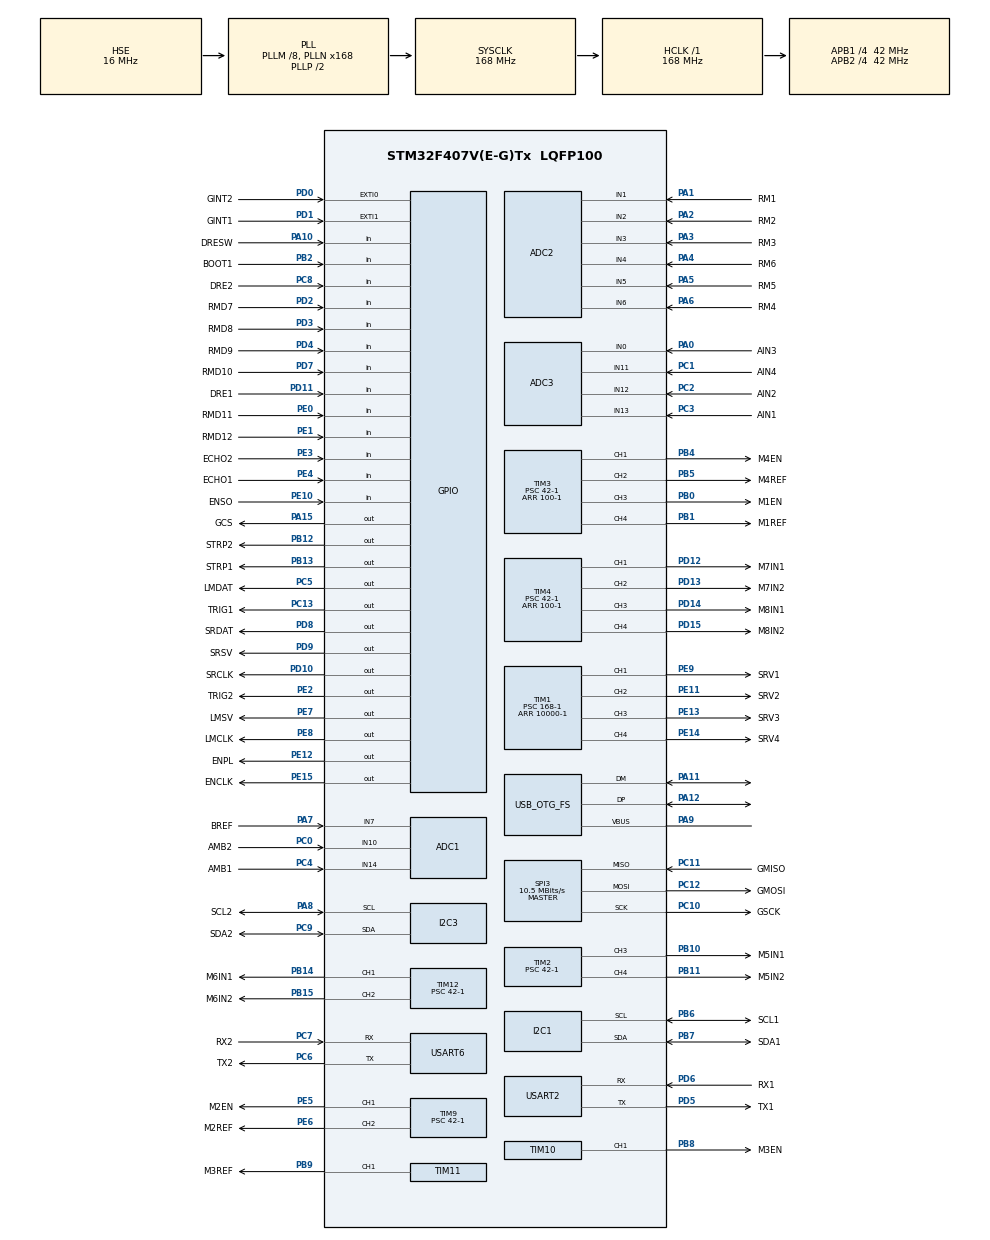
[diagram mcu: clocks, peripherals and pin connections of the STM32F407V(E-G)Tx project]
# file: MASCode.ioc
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ADC1.Channel-0\#ChannelRegularConversion=ADC_CHANNEL_10
ADC1.ClockPrescaler=ADC_CLOCK_SYNC_PCLK_DIV4
ADC1.NbrOfConversionFlag=1
ADC1.Rank-0\#ChannelRegularConversion=1
ADC1.SamplingTime-0\#ChannelRegularConversion=ADC_SAMPLETIME_3CYCLES
ADC1.master=1
ADC2.Channel-0\#ChannelRegularConversion=ADC_CHANNEL_1
ADC2.ClockPrescaler=ADC_CLOCK_SYNC_PCLK_DIV4
ADC2.NbrOfConversionFlag=1
ADC2.Rank-0\#ChannelRegularConversion=1
ADC2.SamplingTime-0\#ChannelRegularConversion=ADC_SAMPLETIME_3CYCLES
ADC3.Channel-0\#ChannelRegularConversion=ADC_CHANNEL_13
ADC3.ClockPrescaler=ADC_CLOCK_SYNC_PCLK_DIV4
ADC3.NbrOfConversionFlag=1
ADC3.Rank-0\#ChannelRegularConversion=1
ADC3.SamplingTime-0\#ChannelRegularConversion=ADC_SAMPLETIME_3CYCLES
Mcu.Family=STM32F4
Mcu.Name=STM32F407V(E-G)Tx
Mcu.Package=LQFP100
NVIC.EXTI0_IRQn=true\:0\:0\:false\:false\:true\:true\:true\:true
NVIC.EXTI1_IRQn=true\:0\:0\:false\:false\:true\:true\:true\:true
NVIC.OTG_FS_IRQn=true\:0\:0\:false\:false\:true\:false\:true\:true
NVIC.PriorityGroup=NVIC_PRIORITYGROUP_4
NVIC.TIM5_IRQn=true\:0\:0\:false\:false\:true\:true\:true\:true
NVIC.TIM7_IRQn=true\:0\:0\:false\:false\:true\:true\:true\:true
PA0-WKUP.GPIO_Label=AIN3
PA0-WKUP.Signal=ADCx_IN0
PA1.GPIO_Label=RM1
PA1.Signal=ADCx_IN1
PA10.GPIO_Label=DRESW
PA10.Signal=GPIO_Input
PA11.Mode=Device_Only
PA11.Signal=USB_OTG_FS_DM
PA12.Mode=Device_Only
PA12.Signal=USB_OTG_FS_DP
PA13.Mode=Trace_Asynchronous_SW
PA13.Signal=SYS_JTMS-SWDIO
PA14.Mode=Trace_Asynchronous_SW
PA14.Signal=SYS_JTCK-SWCLK
PA15.GPIO_Label=GCS
PA15.GPIO_Speed=GPIO_SPEED_FREQ_HIGH
PA15.PinState=GPIO_PIN_SET
PA15.Signal=GPIO_Output
PA2.GPIO_Label=RM2
PA2.Signal=ADCx_IN2
PA3.GPIO_Label=RM3
PA3.Signal=ADCx_IN3
PA4.GPIO_Label=RM6
PA4.Signal=ADCx_IN4
PA5.GPIO_Label=RM5
PA5.Signal=ADCx_IN5
PA6.GPIO_Label=RM4
PA6.Signal=ADCx_IN6
PA7.GPIO_Label=BREF
PA7.Signal=ADCx_IN7
PA8.GPIO_Label=SCL2
PA8.GPIO_Speed=GPIO_SPEED_FREQ_HIGH
PA8.Mode=I2C
PA8.Signal=I2C3_SCL
PA9.Mode=Activate_VBUS
PA9.Signal=USB_OTG_FS_VBUS
PB0.GPIO_Label=M1EN
PB0.Signal=S_TIM3_CH3
PB1.GPIO_Label=M1REF
PB1.Signal=S_TIM3_CH4
PB10.GPIO_Label=M5IN1
PB10.Signal=S_TIM2_CH3
PB11.GPIO_Label=M5IN2
PB11.Signal=S_TIM2_CH4
PB12.GPIO_Label=STRP2
PB12.Signal=GPIO_Output
PB13.GPIO_Label=STRP1
PB13.Signal=GPIO_Output
PB14.GPIO_Label=M6IN1
PB14.Signal=S_TIM12_CH1
PB15.GPIO_Label=M6IN2
PB15.Signal=S_TIM12_CH2
PB2.GPIO_Label=BOOT1
PB2.Signal=GPIO_Input
PB3.Mode=Trace_Asynchronous_SW
PB3.Signal=SYS_JTDO-SWO
PB4.GPIO_Label=M4EN
PB4.Signal=S_TIM3_CH1
PB5.GPIO_Label=M4REF
PB5.Signal=S_TIM3_CH2
PB6.GPIO_Label=SCL1
PB6.GPIO_Speed=GPIO_SPEED_FREQ_HIGH
PB6.Mode=I2C
PB6.Signal=I2C1_SCL
PB7.GPIO_Label=SDA1
PB7.GPIO_Speed=GPIO_SPEED_FREQ_HIGH
PB7.Mode=I2C
PB7.Signal=I2C1_SDA
PB8.GPIO_Label=M3EN
PB8.Signal=S_TIM10_CH1
PB9.GPIO_Label=M3REF
PB9.Signal=S_TIM11_CH1
PC0.GPIO_Label=AMB2
PC0.Signal=ADCx_IN10
PC1.GPIO_Label=AIN4
PC1.Signal=ADCx_IN11
PC10.GPIO_Label=GSCK
PC10.GPIO_Speed=GPIO_SPEED_FREQ_HIGH
PC10.Mode=Full_Duplex_Master
PC10.Signal=SPI3_SCK
PC11.GPIO_Label=GMISO
PC11.GPIO_Speed=GPIO_SPEED_FREQ_HIGH
PC11.Mode=Full_Duplex_Master
PC11.Signal=SPI3_MISO
PC12.GPIO_Label=GMOSI
PC12.GPIO_Speed=GPIO_SPEED_FREQ_HIGH
PC12.Mode=Full_Duplex_Master
PC12.Signal=SPI3_MOSI
PC13-ANTI_TAMP.GPIO_Label=TRIG1
PC13-ANTI_TAMP.Signal=GPIO_Output
PC14-OSC32_IN.Mode=LSE-External-Oscillator
PC14-OSC32_IN.Signal=RCC_OSC32_IN
PC15-OSC32_OUT.Mode=LSE-External-Oscillator
PC15-OSC32_OUT.Signal=RCC_OSC32_OUT
PC2.GPIO_Label=AIN2
PC2.Signal=ADCx_IN12
PC3.GPIO_Label=AIN1
PC3.Signal=ADCx_IN13
PC4.GPIO_Label=AMB1
PC4.Signal=ADCx_IN14
PC5.GPIO_Label=LMDAT
PC5.GPIO_Speed=GPIO_SPEED_FREQ_HIGH
PC5.Signal=GPIO_Output
PC6.GPIO_Label=TX2
PC6.GPIO_Speed=GPIO_SPEED_FREQ_HIGH
PC6.Mode=Asynchronous
PC6.Signal=USART6_TX
PC7.GPIO_Label=RX2
PC7.GPIO_Speed=GPIO_SPEED_FREQ_HIGH
PC7.Mode=Asynchronous
PC7.Signal=USART6_RX
PC8.GPIO_Label=DRE2
PC8.Signal=GPIO_Input
PC9.GPIO_Label=SDA2
PC9.GPIO_Speed=GPIO_SPEED_FREQ_HIGH
PC9.Mode=I2C
PC9.Signal=I2C3_SDA
PD0.GPIO_Label=GINT2
PD0.Signal=GPXTI0
PD1.GPIO_Label=GINT1
PD1.Signal=GPXTI1
PD10.GPIO_Label=SRCLK
PD10.GPIO_Speed=GPIO_SPEED_FREQ_HIGH
PD10.Signal=GPIO_Output
PD11.GPIO_Label=DRE1
PD11.Signal=GPIO_Input
PD12.GPIO_Label=M7IN1
PD12.Signal=S_TIM4_CH1
PD13.GPIO_Label=M7IN2
PD13.Signal=S_TIM4_CH2
PD14.GPIO_Label=M8IN1
PD14.Signal=S_TIM4_CH3
PD15.GPIO_Label=M8IN2
PD15.Signal=S_TIM4_CH4
PD2.GPIO_Label=RMD7
PD2.Signal=GPIO_Input
PD3.GPIO_Label=RMD8
PD3.Signal=GPIO_Input
PD4.GPIO_Label=RMD9
PD4.Signal=GPIO_Input
PD5.GPIO_Label=TX1
PD5.GPIO_Speed=GPIO_SPEED_FREQ_HIGH
PD5.Mode=Asynchronous
PD5.Signal=USART2_TX
PD6.GPIO_Label=RX1
PD6.GPIO_Speed=GPIO_SPEED_FREQ_HIGH
PD6.Mode=Asynchronous
PD6.Signal=USART2_RX
PD7.GPIO_Label=RMD10
PD7.Signal=GPIO_Input
PD8.GPIO_Label=SRDAT
PD8.GPIO_Speed=GPIO_SPEED_FREQ_HIGH
PD8.Signal=GPIO_Output
PD9.GPIO_Label=SRSV
PD9.GPIO_Speed=GPIO_SPEED_FREQ_HIGH
PD9.Signal=GPIO_Output
PE0.GPIO_Label=RMD11
PE0.Signal=GPIO_Input
PE1.GPIO_Label=RMD12
PE1.Signal=GPIO_Input
PE10.GPIO_Label=ENSO
PE10.Signal=GPIO_Input
PE11.GPIO_Label=SRV2
PE11.Signal=S_TIM1_CH2
PE12.GPIO_Label=ENPL
PE12.GPIO_Speed=GPIO_SPEED_FREQ_HIGH
PE12.PinState=GPIO_PIN_RESET
PE12.Signal=GPIO_Output
PE13.GPIO_Label=SRV3
PE13.Signal=S_TIM1_CH3
PE14.GPIO_Label=SRV4
PE14.Signal=S_TIM1_CH4
PE15.GPIO_Label=ENCLK
PE15.GPIO_Speed=GPIO_SPEED_FREQ_HIGH
PE15.PinState=GPIO_PIN_SET
PE15.Signal=GPIO_Output
PE2.GPIO_Label=TRIG2
PE2.Signal=GPIO_Output
PE3.GPIO_Label=ECHO2
PE3.Signal=GPIO_Input
PE4.GPIO_Label=ECHO1
PE4.Signal=GPIO_Input
PE5.GPIO_Label=M2EN
PE5.Signal=S_TIM9_CH1
PE6.GPIO_Label=M2REF
PE6.Signal=S_TIM9_CH2
PE7.GPIO_Label=LMSV
PE7.GPIO_Speed=GPIO_SPEED_FREQ_HIGH
PE7.Signal=GPIO_Output
PE8.GPIO_Label=LMCLK
PE8.GPIO_Speed=GPIO_SPEED_FREQ_HIGH
PE8.Signal=GPIO_Output
PE9.GPIO_Label=SRV1
PE9.Signal=S_TIM1_CH1
PH0-OSC_IN.Mode=HSE-External-Oscillator
PH0-OSC_IN.Signal=RCC_OSC_IN
PH1-OSC_OUT.Mode=HSE-External-Oscillator
PH1-OSC_OUT.Signal=RCC_OSC_OUT
ProjectManager.HeapSize=0x200
ProjectManager.StackSize=0x400
ProjectManager.TargetToolchain=STM32CubeIDE
RCC.48MHZClocksFreq_Value=48000000
RCC.AHBFreq_Value=168000000
RCC.APB1CLKDivider=RCC_HCLK_DIV4
RCC.APB1Freq_Value=42000000
RCC.APB1TimFreq_Value=84000000
RCC.APB2CLKDivider=RCC_HCLK_DIV4
RCC.APB2Freq_Value=42000000
RCC.APB2TimFreq_Value=84000000
RCC.CortexFreq_Value=168000000
RCC.HCLKFreq_Value=168000000
RCC.HSE_VALUE=16000000
RCC.HSI_VALUE=16000000
RCC.PLLM=8
RCC.PLLN=168
RCC.PLLQ=7
RCC.SYSCLKFreq_VALUE=168000000
RCC.SYSCLKSource=RCC_SYSCLKSOURCE_PLLCLK
RCC.VCOOutputFreq_Value=336000000
SH.ADCx_IN0.0=ADC3_IN0,IN0
SH.ADCx_IN1.0=ADC2_IN1,IN1
SH.ADCx_IN10.0=ADC1_IN10,IN10
SH.ADCx_IN11.0=ADC3_IN11,IN11
SH.ADCx_IN12.0=ADC3_IN12,IN12
SH.ADCx_IN13.0=ADC3_IN13,IN13
SH.ADCx_IN14.0=ADC1_IN14,IN14
SH.ADCx_IN2.0=ADC2_IN2,IN2
SH.ADCx_IN3.0=ADC2_IN3,IN3
SH.ADCx_IN4.0=ADC2_IN4,IN4
SH.ADCx_IN5.0=ADC2_IN5,IN5
SH.ADCx_IN6.0=ADC2_IN6,IN6
SH.ADCx_IN7.0=ADC1_IN7,IN7
SH.S_TIM10_CH1.0=TIM10_CH1,PWM Generation1 CH1
SH.S_TIM11_CH1.0=TIM11_CH1,PWM Generation1 CH1
SH.S_TIM12_CH1.0=TIM12_CH1,PWM Generation1 CH1
SH.S_TIM12_CH2.0=TIM12_CH2,PWM Generation2 CH2
SH.S_TIM1_CH1.0=TIM1_CH1,PWM Generation1 CH1
SH.S_TIM1_CH2.0=TIM1_CH2,PWM Generation2 CH2
SH.S_TIM1_CH3.0=TIM1_CH3,PWM Generation3 CH3
SH.S_TIM1_CH4.0=TIM1_CH4,PWM Generation4 CH4
SH.S_TIM2_CH3.0=TIM2_CH3,PWM Generation3 CH3
SH.S_TIM2_CH4.0=TIM2_CH4,PWM Generation4 CH4
SH.S_TIM3_CH1.0=TIM3_CH1,PWM Generation1 CH1
SH.S_TIM3_CH2.0=TIM3_CH2,PWM Generation2 CH2
SH.S_TIM3_CH3.0=TIM3_CH3,PWM Generation3 CH3
SH.S_TIM3_CH4.0=TIM3_CH4,PWM Generation4 CH4
SH.S_TIM4_CH1.0=TIM4_CH1,PWM Generation1 CH1
SH.S_TIM4_CH2.0=TIM4_CH2,PWM Generation2 CH2
SH.S_TIM4_CH3.0=TIM4_CH3,PWM Generation3 CH3
SH.S_TIM4_CH4.0=TIM4_CH4,PWM Generation4 CH4
SH.S_TIM9_CH1.0=TIM9_CH1,PWM Generation1 CH1
SH.S_TIM9_CH2.0=TIM9_CH2,PWM Generation2 CH2
SPI3.BaudRatePrescaler=SPI_BAUDRATEPRESCALER_4
SPI3.CalculateBaudRate=10.5 MBits/s
SPI3.Direction=SPI_DIRECTION_2LINES
SPI3.Mode=SPI_MODE_MASTER
SPI3.VirtualType=VM_MASTER
TIM1.Channel-PWM\ Generation1\ CH1=TIM_CHANNEL_1
TIM1.Channel-PWM\ Generation2\ CH2=TIM_CHANNEL_2
TIM1.Channel-PWM\ Generation3\ CH3=TIM_CHANNEL_3
TIM1.Channel-PWM\ Generation4\ CH4=TIM_CHANNEL_4
TIM1.Period=10000-1
TIM1.Prescaler=168-1
TIM10.Channel=TIM_CHANNEL_1
TIM10.Period=100-1
TIM10.Prescaler=42-1
TIM11.Channel=TIM_CHANNEL_1
TIM11.Period=100-1
TIM11.Prescaler=42-1
TIM12.Channel-PWM\ Generation1\ CH1=TIM_CHANNEL_1
TIM12.Channel-PWM\ Generation2\ CH2=TIM_CHANNEL_2
TIM12.Period=100-1
TIM12.Prescaler=42-1
TIM2.Channel-PWM\ Generation3\ CH3=TIM_CHANNEL_3
TIM2.Channel-PWM\ Generation4\ CH4=TIM_CHANNEL_4
TIM2.Period=100-1
TIM2.Prescaler=42-1
TIM3.Channel-PWM\ Generation1\ CH1=TIM_CHANNEL_1
TIM3.Channel-PWM\ Generation2\ CH2=TIM_CHANNEL_2
TIM3.Channel-PWM\ Generation3\ CH3=TIM_CHANNEL_3
TIM3.Channel-PWM\ Generation4\ CH4=TIM_CHANNEL_4
TIM3.Period=100-1
TIM3.Prescaler=42-1
TIM4.Channel-PWM\ Generation1\ CH1=TIM_CHANNEL_1
TIM4.Channel-PWM\ Generation2\ CH2=TIM_CHANNEL_2
TIM4.Channel-PWM\ Generation3\ CH3=TIM_CHANNEL_3
TIM4.Channel-PWM\ Generation4\ CH4=TIM_CHANNEL_4
TIM4.Period=100-1
TIM4.Prescaler=42-1
TIM5.Period=20-1
TIM5.Prescaler=42-1
TIM7.Prescaler=12
TIM9.Channel-PWM\ Generation1\ CH1=TIM_CHANNEL_1
TIM9.Channel-PWM\ Generation2\ CH2=TIM_CHANNEL_2
TIM9.Period=100-1
TIM9.Prescaler=42-1
USART2.VirtualMode=VM_ASYNC
USART6.VirtualMode=VM_ASYNC
USB_DEVICE.CLASS_NAME_FS=CDC
USB_DEVICE.PRODUCT_STRING_CDC_FS=Electrozilla Virtual ComPort
USB_DEVICE.VirtualMode-CDC_FS=Cdc
USB_DEVICE.VirtualModeFS=Cdc_FS
USB_OTG_FS.VirtualMode=Device_Only
VP_ADC1_TempSens_Input.Mode=IN-TempSens
VP_TIM10_VS_ClockSourceINT.Mode=Enable_Timer
VP_TIM11_VS_ClockSourceINT.Mode=Enable_Timer
VP_TIM12_VS_ClockSourceINT.Mode=Internal
VP_TIM1_VS_ClockSourceINT.Mode=Internal
VP_TIM2_VS_ClockSourceINT.Mode=Internal
VP_TIM3_VS_ClockSourceINT.Mode=Internal
VP_TIM4_VS_ClockSourceINT.Mode=Internal
VP_TIM5_VS_ClockSourceINT.Mode=Internal
VP_TIM7_VS_ClockSourceINT.Mode=Enable_Timer
VP_TIM9_VS_ClockSourceINT.Mode=Internal
VP_USB_DEVICE_VS_USB_DEVICE_CDC_FS.Mode=CDC_FS
board=custom

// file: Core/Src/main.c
/* USER CODE BEGIN Header */
/**
 ******************************************************************************
 * @file           : main.c
 * @brief          : Setup Program body
 ******************************************************************************
 * @attention
 *
 * Copyright (c) 2024 STMicroelectronics.
 * All rights reserved.
 *
 * This software is licensed under terms that can be found in the LICENSE file
 * in the root directory of this software component.
 * If no LICENSE file comes with this software, it is provided AS-IS.
 *
 ******************************************************************************
 */

/*
 * Connection info
 *
 * ADC1 - AMB1, AMB2, BREF
 * ADC2 - RM1:6
 * ADC3 - AIN1:4
 *
 * TIM1 - SRV1:4
 * TIM2 - M5
 * TIM3 - M1, M4
 * TIM4 - M7, M8
 * TIM9 - M2
 * TIM10 - M3EN
 * TIM11 - M3REF
 * TIM12 - M6
 *
 * TIM5 - Shift Register Frames
 * TIM7 - Digital Read Frames
 *
 * I2C1 - External
 * I2C2 - OLED
 *
 * SPI3 - Gyroscope/Accelerometer + Temperature
 *
 * UART2 - External 1
 * UART6 - External 2
 */

/* USER CODE END Header */
#include "main.h"
#include "usb_device.h"

/* USER CODE BEGIN Includes */
#include "usbd_cdc_if.h"
#include "control.h"
#include "registers.h"
/* USER CODE END Includes */

ADC_HandleTypeDef hadc1;
ADC_HandleTypeDef hadc2;
ADC_HandleTypeDef hadc3;

I2C_HandleTypeDef hi2c1;
I2C_HandleTypeDef hi2c3;

SPI_HandleTypeDef hspi3;

TIM_HandleTypeDef htim1;
TIM_HandleTypeDef htim2;
TIM_HandleTypeDef htim3;
TIM_HandleTypeDef htim4;
TIM_HandleTypeDef htim5;
TIM_HandleTypeDef htim7;
TIM_HandleTypeDef htim9;
TIM_HandleTypeDef htim10;
TIM_HandleTypeDef htim11;
TIM_HandleTypeDef htim12;

UART_HandleTypeDef huart2;
UART_HandleTypeDef huart6;

void SystemClock_Config(void);
static void MX_GPIO_Init(void);
static void MX_ADC1_Init(void);
static void MX_I2C1_Init(void);
static void MX_I2C3_Init(void);
static void MX_SPI3_Init(void);
static void MX_TIM1_Init(void);
static void MX_TIM2_Init(void);
static void MX_TIM3_Init(void);
static void MX_TIM4_Init(void);
static void MX_TIM9_Init(void);
static void MX_TIM10_Init(void);
static void MX_TIM11_Init(void);
static void MX_TIM12_Init(void);
static void MX_USART2_UART_Init(void);
static void MX_USART6_UART_Init(void);
static void MX_ADC2_Init(void);
static void MX_ADC3_Init(void);
static void MX_TIM5_Init(void);
static void MX_TIM7_Init(void);

int main(void)
{

  /* MCU Configuration--------------------------------------------------------*/

  /* Reset of all peripherals, Initializes the Flash interface and the Systick. */
  HAL_Init();

  /* Configure the system clock */
  SystemClock_Config();

  /* Initialize all configured peripherals */
  MX_GPIO_Init();
  MX_ADC1_Init();
  MX_I2C1_Init();
  MX_I2C3_Init();
  MX_SPI3_Init();
  MX_TIM1_Init();
  MX_TIM2_Init();
  MX_TIM3_Init();
  MX_TIM4_Init();
  MX_TIM9_Init();
  MX_TIM10_Init();
  MX_TIM11_Init();
  MX_TIM12_Init();
  MX_USART2_UART_Init();
  MX_USART6_UART_Init();
  MX_ADC2_Init();
  MX_ADC3_Init();
  MX_USB_DEVICE_Init();
  MX_TIM5_Init();
  MX_TIM7_Init();
  /* USER CODE BEGIN 2 */
	HAL_Delay(10);

	Control_Init();

	HAL_Delay(10);
  /* USER CODE END 2 */

  /* Infinite loop */
  /* USER CODE BEGIN WHILE */
	while (1) {
		Control_Loop();
    /* USER CODE END WHILE */

	}
}

void SystemClock_Config(void)
{
  RCC_OscInitTypeDef RCC_OscInitStruct = {0};
  RCC_ClkInitTypeDef RCC_ClkInitStruct = {0};

  /** Configure the main internal regulator output voltage
  */
  __HAL_RCC_PWR_CLK_ENABLE();
  __HAL_PWR_VOLTAGESCALING_CONFIG(PWR_REGULATOR_VOLTAGE_SCALE1);

  /** Initializes the RCC Oscillators according to the specified parameters
  * in the RCC_OscInitTypeDef structure.
  */
  RCC_OscInitStruct.OscillatorType = RCC_OSCILLATORTYPE_HSE;
  RCC_OscInitStruct.HSEState = RCC_HSE_ON;
  RCC_OscInitStruct.PLL.PLLState = RCC_PLL_ON;
  RCC_OscInitStruct.PLL.PLLSource = RCC_PLLSOURCE_HSE;
  RCC_OscInitStruct.PLL.PLLM = 8;
  RCC_OscInitStruct.PLL.PLLN = 168;
  RCC_OscInitStruct.PLL.PLLP = RCC_PLLP_DIV2;
  RCC_OscInitStruct.PLL.PLLQ = 7;
  if (HAL_RCC_OscConfig(&RCC_OscInitStruct) != HAL_OK)
  {
    Error_Handler();
  }

  /** Initializes the CPU, AHB and APB buses clocks
  */
  RCC_ClkInitStruct.ClockType = RCC_CLOCKTYPE_HCLK|RCC_CLOCKTYPE_SYSCLK
                              |RCC_CLOCKTYPE_PCLK1|RCC_CLOCKTYPE_PCLK2;
  RCC_ClkInitStruct.SYSCLKSource = RCC_SYSCLKSOURCE_PLLCLK;
  RCC_ClkInitStruct.AHBCLKDivider = RCC_SYSCLK_DIV1;
  RCC_ClkInitStruct.APB1CLKDivider = RCC_HCLK_DIV4;
  RCC_ClkInitStruct.APB2CLKDivider = RCC_HCLK_DIV4;

  if (HAL_RCC_ClockConfig(&RCC_ClkInitStruct, FLASH_LATENCY_5) != HAL_OK)
  {
    Error_Handler();
  }
}

static void MX_ADC1_Init(void)
{

  ADC_ChannelConfTypeDef sConfig = {0};

  /** Configure the global features of the ADC (Clock, Resolution, Data Alignment and number of conversion)
  */
  hadc1.Instance = ADC1;
  hadc1.Init.ClockPrescaler = ADC_CLOCK_SYNC_PCLK_DIV4;
  hadc1.Init.Resolution = ADC_RESOLUTION_12B;
  hadc1.Init.ScanConvMode = DISABLE;
  hadc1.Init.ContinuousConvMode = DISABLE;
  hadc1.Init.DiscontinuousConvMode = DISABLE;
  hadc1.Init.ExternalTrigConvEdge = ADC_EXTERNALTRIGCONVEDGE_NONE;
  hadc1.Init.ExternalTrigConv = ADC_SOFTWARE_START;
  hadc1.Init.DataAlign = ADC_DATAALIGN_RIGHT;
  hadc1.Init.NbrOfConversion = 1;
  hadc1.Init.DMAContinuousRequests = DISABLE;
  hadc1.Init.EOCSelection = ADC_EOC_SINGLE_CONV;
  if (HAL_ADC_Init(&hadc1) != HAL_OK)
  {
    Error_Handler();
  }

  /** Configure for the selected ADC regular channel its corresponding rank in the sequencer and its sample time.
  */
  sConfig.Channel = ADC_CHANNEL_10;
  sConfig.Rank = 1;
  sConfig.SamplingTime = ADC_SAMPLETIME_3CYCLES;
  if (HAL_ADC_ConfigChannel(&hadc1, &sConfig) != HAL_OK)
  {
    Error_Handler();
  }

}

static void MX_ADC2_Init(void)
{

  ADC_ChannelConfTypeDef sConfig = {0};

  /** Configure the global features of the ADC (Clock, Resolution, Data Alignment and number of conversion)
  */
  hadc2.Instance = ADC2;
  hadc2.Init.ClockPrescaler = ADC_CLOCK_SYNC_PCLK_DIV4;
  hadc2.Init.Resolution = ADC_RESOLUTION_12B;
  hadc2.Init.ScanConvMode = DISABLE;
  hadc2.Init.ContinuousConvMode = DISABLE;
  hadc2.Init.DiscontinuousConvMode = DISABLE;
  hadc2.Init.ExternalTrigConvEdge = ADC_EXTERNALTRIGCONVEDGE_NONE;
  hadc2.Init.ExternalTrigConv = ADC_SOFTWARE_START;
  hadc2.Init.DataAlign = ADC_DATAALIGN_RIGHT;
  hadc2.Init.NbrOfConversion = 1;
  hadc2.Init.DMAContinuousRequests = DISABLE;
  hadc2.Init.EOCSelection = ADC_EOC_SINGLE_CONV;
  if (HAL_ADC_Init(&hadc2) != HAL_OK)
  {
    Error_Handler();
  }

  /** Configure for the selected ADC regular channel its corresponding rank in the sequencer and its sample time.
  */
  sConfig.Channel = ADC_CHANNEL_1;
  sConfig.Rank = 1;
  sConfig.SamplingTime = ADC_SAMPLETIME_3CYCLES;
  if (HAL_ADC_ConfigChannel(&hadc2, &sConfig) != HAL_OK)
  {
    Error_Handler();
  }

}

static void MX_ADC3_Init(void)
{

  ADC_ChannelConfTypeDef sConfig = {0};

  /** Configure the global features of the ADC (Clock, Resolution, Data Alignment and number of conversion)
  */
  hadc3.Instance = ADC3;
  hadc3.Init.ClockPrescaler = ADC_CLOCK_SYNC_PCLK_DIV4;
  hadc3.Init.Resolution = ADC_RESOLUTION_12B;
  hadc3.Init.ScanConvMode = DISABLE;
  hadc3.Init.ContinuousConvMode = DISABLE;
  hadc3.Init.DiscontinuousConvMode = DISABLE;
  hadc3.Init.ExternalTrigConvEdge = ADC_EXTERNALTRIGCONVEDGE_NONE;
  hadc3.Init.ExternalTrigConv = ADC_SOFTWARE_START;
  hadc3.Init.DataAlign = ADC_DATAALIGN_RIGHT;
  hadc3.Init.NbrOfConversion = 1;
  hadc3.Init.DMAContinuousRequests = DISABLE;
  hadc3.Init.EOCSelection = ADC_EOC_SINGLE_CONV;
  if (HAL_ADC_Init(&hadc3) != HAL_OK)
  {
    Error_Handler();
  }

  /** Configure for the selected ADC regular channel its corresponding rank in the sequencer and its sample time.
  */
  sConfig.Channel = ADC_CHANNEL_13;
  sConfig.Rank = 1;
  sConfig.SamplingTime = ADC_SAMPLETIME_3CYCLES;
  if (HAL_ADC_ConfigChannel(&hadc3, &sConfig) != HAL_OK)
  {
    Error_Handler();
  }

}

static void MX_I2C1_Init(void)
{

  hi2c1.Instance = I2C1;
  hi2c1.Init.ClockSpeed = 100000;
  hi2c1.Init.DutyCycle = I2C_DUTYCYCLE_2;
  hi2c1.Init.OwnAddress1 = 0;
  hi2c1.Init.AddressingMode = I2C_ADDRESSINGMODE_7BIT;
  hi2c1.Init.DualAddressMode = I2C_DUALADDRESS_DISABLE;
  hi2c1.Init.OwnAddress2 = 0;
  hi2c1.Init.GeneralCallMode = I2C_GENERALCALL_DISABLE;
  hi2c1.Init.NoStretchMode = I2C_NOSTRETCH_DISABLE;
  if (HAL_I2C_Init(&hi2c1) != HAL_OK)
  {
    Error_Handler();
  }

}

static void MX_I2C3_Init(void)
{

  hi2c3.Instance = I2C3;
  hi2c3.Init.ClockSpeed = 100000;
  hi2c3.Init.DutyCycle = I2C_DUTYCYCLE_2;
  hi2c3.Init.OwnAddress1 = 0;
  hi2c3.Init.AddressingMode = I2C_ADDRESSINGMODE_7BIT;
  hi2c3.Init.DualAddressMode = I2C_DUALADDRESS_DISABLE;
  hi2c3.Init.OwnAddress2 = 0;
  hi2c3.Init.GeneralCallMode = I2C_GENERALCALL_DISABLE;
  hi2c3.Init.NoStretchMode = I2C_NOSTRETCH_DISABLE;
  if (HAL_I2C_Init(&hi2c3) != HAL_OK)
  {
    Error_Handler();
  }

}

static void MX_SPI3_Init(void)
{

  /* SPI3 parameter configuration*/
  hspi3.Instance = SPI3;
  hspi3.Init.Mode = SPI_MODE_MASTER;
  hspi3.Init.Direction = SPI_DIRECTION_2LINES;
  hspi3.Init.DataSize = SPI_DATASIZE_8BIT;
  hspi3.Init.CLKPolarity = SPI_POLARITY_LOW;
  hspi3.Init.CLKPhase = SPI_PHASE_1EDGE;
  hspi3.Init.NSS = SPI_NSS_SOFT;
  hspi3.Init.BaudRatePrescaler = SPI_BAUDRATEPRESCALER_4;
  hspi3.Init.FirstBit = SPI_FIRSTBIT_MSB;
  hspi3.Init.TIMode = SPI_TIMODE_DISABLE;
  hspi3.Init.CRCCalculation = SPI_CRCCALCULATION_DISABLE;
  hspi3.Init.CRCPolynomial = 10;
  if (HAL_SPI_Init(&hspi3) != HAL_OK)
  {
    Error_Handler();
  }

}

static void MX_TIM1_Init(void)
{

  TIM_ClockConfigTypeDef sClockSourceConfig = {0};
  TIM_MasterConfigTypeDef sMasterConfig = {0};
  TIM_OC_InitTypeDef sConfigOC = {0};
  TIM_BreakDeadTimeConfigTypeDef sBreakDeadTimeConfig = {0};

  htim1.Instance = TIM1;
  htim1.Init.Prescaler = 168-1;
  htim1.Init.CounterMode = TIM_COUNTERMODE_UP;
  htim1.Init.Period = 10000-1;
  htim1.Init.ClockDivision = TIM_CLOCKDIVISION_DIV1;
  htim1.Init.RepetitionCounter = 0;
  htim1.Init.AutoReloadPreload = TIM_AUTORELOAD_PRELOAD_DISABLE;
  if (HAL_TIM_Base_Init(&htim1) != HAL_OK)
  {
    Error_Handler();
  }
  sClockSourceConfig.ClockSource = TIM_CLOCKSOURCE_INTERNAL;
  if (HAL_TIM_ConfigClockSource(&htim1, &sClockSourceConfig) != HAL_OK)
  {
    Error_Handler();
  }
  if (HAL_TIM_PWM_Init(&htim1) != HAL_OK)
  {
    Error_Handler();
  }
  sMasterConfig.MasterOutputTrigger = TIM_TRGO_RESET;
  sMasterConfig.MasterSlaveMode = TIM_MASTERSLAVEMODE_DISABLE;
  if (HAL_TIMEx_MasterConfigSynchronization(&htim1, &sMasterConfig) != HAL_OK)
  {
    Error_Handler();
  }
  sConfigOC.OCMode = TIM_OCMODE_PWM1;
  sConfigOC.Pulse = 0;
  sConfigOC.OCPolarity = TIM_OCPOLARITY_HIGH;
  sConfigOC.OCNPolarity = TIM_OCNPOLARITY_HIGH;
  sConfigOC.OCFastMode = TIM_OCFAST_DISABLE;
  sConfigOC.OCIdleState = TIM_OCIDLESTATE_RESET;
  sConfigOC.OCNIdleState = TIM_OCNIDLESTATE_RESET;
  if (HAL_TIM_PWM_ConfigChannel(&htim1, &sConfigOC, TIM_CHANNEL_1) != HAL_OK)
  {
    Error_Handler();
  }
  if (HAL_TIM_PWM_ConfigChannel(&htim1, &sConfigOC, TIM_CHANNEL_2) != HAL_OK)
  {
    Error_Handler();
  }
  if (HAL_TIM_PWM_ConfigChannel(&htim1, &sConfigOC, TIM_CHANNEL_3) != HAL_OK)
  {
    Error_Handler();
  }
  if (HAL_TIM_PWM_ConfigChannel(&htim1, &sConfigOC, TIM_CHANNEL_4) != HAL_OK)
  {
    Error_Handler();
  }
  sBreakDeadTimeConfig.OffStateRunMode = TIM_OSSR_DISABLE;
  sBreakDeadTimeConfig.OffStateIDLEMode = TIM_OSSI_DISABLE;
  sBreakDeadTimeConfig.LockLevel = TIM_LOCKLEVEL_OFF;
  sBreakDeadTimeConfig.DeadTime = 0;
  sBreakDeadTimeConfig.BreakState = TIM_BREAK_DISABLE;
  sBreakDeadTimeConfig.BreakPolarity = TIM_BREAKPOLARITY_HIGH;
  sBreakDeadTimeConfig.AutomaticOutput = TIM_AUTOMATICOUTPUT_DISABLE;
  if (HAL_TIMEx_ConfigBreakDeadTime(&htim1, &sBreakDeadTimeConfig) != HAL_OK)
  {
    Error_Handler();
  }
  HAL_TIM_MspPostInit(&htim1);

}

static void MX_TIM2_Init(void)
{

  TIM_ClockConfigTypeDef sClockSourceConfig = {0};
  TIM_MasterConfigTypeDef sMasterConfig = {0};
  TIM_OC_InitTypeDef sConfigOC = {0};

  htim2.Instance = TIM2;
  htim2.Init.Prescaler = 42-1;
  htim2.Init.CounterMode = TIM_COUNTERMODE_UP;
  htim2.Init.Period = 100-1;
  htim2.Init.ClockDivision = TIM_CLOCKDIVISION_DIV1;
  htim2.Init.AutoReloadPreload = TIM_AUTORELOAD_PRELOAD_DISABLE;
  if (HAL_TIM_Base_Init(&htim2) != HAL_OK)
  {
    Error_Handler();
  }
  sClockSourceConfig.ClockSource = TIM_CLOCKSOURCE_INTERNAL;
  if (HAL_TIM_ConfigClockSource(&htim2, &sClockSourceConfig) != HAL_OK)
  {
    Error_Handler();
  }
  if (HAL_TIM_PWM_Init(&htim2) != HAL_OK)
  {
    Error_Handler();
  }
  sMasterConfig.MasterOutputTrigger = TIM_TRGO_RESET;
  sMasterConfig.MasterSlaveMode = TIM_MASTERSLAVEMODE_DISABLE;
  if (HAL_TIMEx_MasterConfigSynchronization(&htim2, &sMasterConfig) != HAL_OK)
  {
    Error_Handler();
  }
  sConfigOC.OCMode = TIM_OCMODE_PWM1;
  sConfigOC.Pulse = 0;
  sConfigOC.OCPolarity = TIM_OCPOLARITY_HIGH;
  sConfigOC.OCFastMode = TIM_OCFAST_DISABLE;
  if (HAL_TIM_PWM_ConfigChannel(&htim2, &sConfigOC, TIM_CHANNEL_3) != HAL_OK)
  {
    Error_Handler();
  }
  if (HAL_TIM_PWM_ConfigChannel(&htim2, &sConfigOC, TIM_CHANNEL_4) != HAL_OK)
  {
    Error_Handler();
  }
  HAL_TIM_MspPostInit(&htim2);

}

static void MX_TIM3_Init(void)
{

  TIM_ClockConfigTypeDef sClockSourceConfig = {0};
  TIM_MasterConfigTypeDef sMasterConfig = {0};
  TIM_OC_InitTypeDef sConfigOC = {0};

  htim3.Instance = TIM3;
  htim3.Init.Prescaler = 42-1;
  htim3.Init.CounterMode = TIM_COUNTERMODE_UP;
  htim3.Init.Period = 100-1;
  htim3.Init.ClockDivision = TIM_CLOCKDIVISION_DIV1;
  htim3.Init.AutoReloadPreload = TIM_AUTORELOAD_PRELOAD_DISABLE;
  if (HAL_TIM_Base_Init(&htim3) != HAL_OK)
  {
    Error_Handler();
  }
  sClockSourceConfig.ClockSource = TIM_CLOCKSOURCE_INTERNAL;
  if (HAL_TIM_ConfigClockSource(&htim3, &sClockSourceConfig) != HAL_OK)
  {
    Error_Handler();
  }
  if (HAL_TIM_PWM_Init(&htim3) != HAL_OK)
  {
    Error_Handler();
  }
  sMasterConfig.MasterOutputTrigger = TIM_TRGO_RESET;
  sMasterConfig.MasterSlaveMode = TIM_MASTERSLAVEMODE_DISABLE;
  if (HAL_TIMEx_MasterConfigSynchronization(&htim3, &sMasterConfig) != HAL_OK)
  {
    Error_Handler();
  }
  sConfigOC.OCMode = TIM_OCMODE_PWM1;
  sConfigOC.Pulse = 0;
  sConfigOC.OCPolarity = TIM_OCPOLARITY_HIGH;
  sConfigOC.OCFastMode = TIM_OCFAST_DISABLE;
  if (HAL_TIM_PWM_ConfigChannel(&htim3, &sConfigOC, TIM_CHANNEL_1) != HAL_OK)
  {
    Error_Handler();
  }
  if (HAL_TIM_PWM_ConfigChannel(&htim3, &sConfigOC, TIM_CHANNEL_2) != HAL_OK)
  {
    Error_Handler();
  }
  if (HAL_TIM_PWM_ConfigChannel(&htim3, &sConfigOC, TIM_CHANNEL_3) != HAL_OK)
  {
    Error_Handler();
  }
  if (HAL_TIM_PWM_ConfigChannel(&htim3, &sConfigOC, TIM_CHANNEL_4) != HAL_OK)
  {
    Error_Handler();
  }
  HAL_TIM_MspPostInit(&htim3);

}

static void MX_TIM4_Init(void)
{

  TIM_ClockConfigTypeDef sClockSourceConfig = {0};
  TIM_MasterConfigTypeDef sMasterConfig = {0};
  TIM_OC_InitTypeDef sConfigOC = {0};

  htim4.Instance = TIM4;
  htim4.Init.Prescaler = 42-1;
  htim4.Init.CounterMode = TIM_COUNTERMODE_UP;
  htim4.Init.Period = 100-1;
  htim4.Init.ClockDivision = TIM_CLOCKDIVISION_DIV1;
  htim4.Init.AutoReloadPreload = TIM_AUTORELOAD_PRELOAD_DISABLE;
  if (HAL_TIM_Base_Init(&htim4) != HAL_OK)
  {
    Error_Handler();
  }
  sClockSourceConfig.ClockSource = TIM_CLOCKSOURCE_INTERNAL;
  if (HAL_TIM_ConfigClockSource(&htim4, &sClockSourceConfig) != HAL_OK)
  {
    Error_Handler();
  }
  if (HAL_TIM_PWM_Init(&htim4) != HAL_OK)
  {
    Error_Handler();
  }
  sMasterConfig.MasterOutputTrigger = TIM_TRGO_RESET;
  sMasterConfig.MasterSlaveMode = TIM_MASTERSLAVEMODE_DISABLE;
  if (HAL_TIMEx_MasterConfigSynchronization(&htim4, &sMasterConfig) != HAL_OK)
  {
    Error_Handler();
  }
  sConfigOC.OCMode = TIM_OCMODE_PWM1;
  sConfigOC.Pulse = 0;
  sConfigOC.OCPolarity = TIM_OCPOLARITY_HIGH;
  sConfigOC.OCFastMode = TIM_OCFAST_DISABLE;
  if (HAL_TIM_PWM_ConfigChannel(&htim4, &sConfigOC, TIM_CHANNEL_1) != HAL_OK)
  {
    Error_Handler();
  }
  if (HAL_TIM_PWM_ConfigChannel(&htim4, &sConfigOC, TIM_CHANNEL_2) != HAL_OK)
  {
    Error_Handler();
  }
  if (HAL_TIM_PWM_ConfigChannel(&htim4, &sConfigOC, TIM_CHANNEL_3) != HAL_OK)
  {
    Error_Handler();
  }
  if (HAL_TIM_PWM_ConfigChannel(&htim4, &sConfigOC, TIM_CHANNEL_4) != HAL_OK)
  {
    Error_Handler();
  }
  HAL_TIM_MspPostInit(&htim4);

}

static void MX_TIM5_Init(void)
{

  TIM_ClockConfigTypeDef sClockSourceConfig = {0};
  TIM_MasterConfigTypeDef sMasterConfig = {0};

  htim5.Instance = TIM5;
  htim5.Init.Prescaler = 42-1;
  htim5.Init.CounterMode = TIM_COUNTERMODE_UP;
  htim5.Init.Period = 20-1;
  htim5.Init.ClockDivision = TIM_CLOCKDIVISION_DIV1;
  htim5.Init.AutoReloadPreload = TIM_AUTORELOAD_PRELOAD_DISABLE;
  if (HAL_TIM_Base_Init(&htim5) != HAL_OK)
  {
    Error_Handler();
  }
  sClockSourceConfig.ClockSource = TIM_CLOCKSOURCE_INTERNAL;
  if (HAL_TIM_ConfigClockSource(&htim5, &sClockSourceConfig) != HAL_OK)
  {
    Error_Handler();
  }
  sMasterConfig.MasterOutputTrigger = TIM_TRGO_RESET;
  sMasterConfig.MasterSlaveMode = TIM_MASTERSLAVEMODE_DISABLE;
  if (HAL_TIMEx_MasterConfigSynchronization(&htim5, &sMasterConfig) != HAL_OK)
  {
    Error_Handler();
  }
  /* USER CODE BEGIN TIM5_Init 2 */
	if (HAL_TIM_Base_Start_IT(&htim5) != HAL_OK) {
		Error_Handler();
	}
  /* USER CODE END TIM5_Init 2 */

}

static void MX_TIM7_Init(void)
{

  TIM_MasterConfigTypeDef sMasterConfig = {0};

  htim7.Instance = TIM7;
  htim7.Init.Prescaler = 12;
  htim7.Init.CounterMode = TIM_COUNTERMODE_UP;
  htim7.Init.Period = 65535;
  htim7.Init.AutoReloadPreload = TIM_AUTORELOAD_PRELOAD_DISABLE;
  if (HAL_TIM_Base_Init(&htim7) != HAL_OK)
  {
    Error_Handler();
  }
  sMasterConfig.MasterOutputTrigger = TIM_TRGO_RESET;
  sMasterConfig.MasterSlaveMode = TIM_MASTERSLAVEMODE_DISABLE;
  if (HAL_TIMEx_MasterConfigSynchronization(&htim7, &sMasterConfig) != HAL_OK)
  {
    Error_Handler();
  }

}

static void MX_TIM9_Init(void)
{

  TIM_ClockConfigTypeDef sClockSourceConfig = {0};
  TIM_OC_InitTypeDef sConfigOC = {0};

  htim9.Instance = TIM9;
  htim9.Init.Prescaler = 42-1;
  htim9.Init.CounterMode = TIM_COUNTERMODE_UP;
  htim9.Init.Period = 100-1;
  htim9.Init.ClockDivision = TIM_CLOCKDIVISION_DIV1;
  htim9.Init.AutoReloadPreload = TIM_AUTORELOAD_PRELOAD_DISABLE;
  if (HAL_TIM_Base_Init(&htim9) != HAL_OK)
  {
    Error_Handler();
  }
  sClockSourceConfig.ClockSource = TIM_CLOCKSOURCE_INTERNAL;
  if (HAL_TIM_ConfigClockSource(&htim9, &sClockSourceConfig) != HAL_OK)
  {
    Error_Handler();
  }
  if (HAL_TIM_PWM_Init(&htim9) != HAL_OK)
  {
    Error_Handler();
  }
  sConfigOC.OCMode = TIM_OCMODE_PWM1;
  sConfigOC.Pulse = 0;
  sConfigOC.OCPolarity = TIM_OCPOLARITY_HIGH;
  sConfigOC.OCFastMode = TIM_OCFAST_DISABLE;
  if (HAL_TIM_PWM_ConfigChannel(&htim9, &sConfigOC, TIM_CHANNEL_1) != HAL_OK)
  {
    Error_Handler();
  }
  if (HAL_TIM_PWM_ConfigChannel(&htim9, &sConfigOC, TIM_CHANNEL_2) != HAL_OK)
  {
    Error_Handler();
  }
  HAL_TIM_MspPostInit(&htim9);

}

static void MX_TIM10_Init(void)
{

  TIM_OC_InitTypeDef sConfigOC = {0};

  htim10.Instance = TIM10;
  htim10.Init.Prescaler = 42-1;
  htim10.Init.CounterMode = TIM_COUNTERMODE_UP;
  htim10.Init.Period = 100-1;
  htim10.Init.ClockDivision = TIM_CLOCKDIVISION_DIV1;
  htim10.Init.AutoReloadPreload = TIM_AUTORELOAD_PRELOAD_DISABLE;
  if (HAL_TIM_Base_Init(&htim10) != HAL_OK)
  {
    Error_Handler();
  }
  if (HAL_TIM_PWM_Init(&htim10) != HAL_OK)
  {
    Error_Handler();
  }
  sConfigOC.OCMode = TIM_OCMODE_PWM1;
  sConfigOC.Pulse = 0;
  sConfigOC.OCPolarity = TIM_OCPOLARITY_HIGH;
  sConfigOC.OCFastMode = TIM_OCFAST_DISABLE;
  if (HAL_TIM_PWM_ConfigChannel(&htim10, &sConfigOC, TIM_CHANNEL_1) != HAL_OK)
  {
    Error_Handler();
  }
  HAL_TIM_MspPostInit(&htim10);

}

static void MX_TIM11_Init(void)
{

  TIM_OC_InitTypeDef sConfigOC = {0};

  htim11.Instance = TIM11;
  htim11.Init.Prescaler = 42-1;
  htim11.Init.CounterMode = TIM_COUNTERMODE_UP;
  htim11.Init.Period = 100-1;
  htim11.Init.ClockDivision = TIM_CLOCKDIVISION_DIV1;
  htim11.Init.AutoReloadPreload = TIM_AUTORELOAD_PRELOAD_DISABLE;
  if (HAL_TIM_Base_Init(&htim11) != HAL_OK)
  {
    Error_Handler();
  }
  if (HAL_TIM_PWM_Init(&htim11) != HAL_OK)
  {
    Error_Handler();
  }
  sConfigOC.OCMode = TIM_OCMODE_PWM1;
  sConfigOC.Pulse = 0;
  sConfigOC.OCPolarity = TIM_OCPOLARITY_HIGH;
  sConfigOC.OCFastMode = TIM_OCFAST_DISABLE;
  if (HAL_TIM_PWM_ConfigChannel(&htim11, &sConfigOC, TIM_CHANNEL_1) != HAL_OK)
  {
    Error_Handler();
  }
  HAL_TIM_MspPostInit(&htim11);

}

static void MX_TIM12_Init(void)
{

  TIM_ClockConfigTypeDef sClockSourceConfig = {0};
  TIM_OC_InitTypeDef sConfigOC = {0};

  htim12.Instance = TIM12;
  htim12.Init.Prescaler = 42-1;
  htim12.Init.CounterMode = TIM_COUNTERMODE_UP;
  htim12.Init.Period = 100-1;
  htim12.Init.ClockDivision = TIM_CLOCKDIVISION_DIV1;
  htim12.Init.AutoReloadPreload = TIM_AUTORELOAD_PRELOAD_DISABLE;
  if (HAL_TIM_Base_Init(&htim12) != HAL_OK)
  {
    Error_Handler();
  }
  sClockSourceConfig.ClockSource = TIM_CLOCKSOURCE_INTERNAL;
  if (HAL_TIM_ConfigClockSource(&htim12, &sClockSourceConfig) != HAL_OK)
  {
    Error_Handler();
  }
  if (HAL_TIM_PWM_Init(&htim12) != HAL_OK)
  {
    Error_Handler();
  }
  sConfigOC.OCMode = TIM_OCMODE_PWM1;
  sConfigOC.Pulse = 0;
  sConfigOC.OCPolarity = TIM_OCPOLARITY_HIGH;
  sConfigOC.OCFastMode = TIM_OCFAST_DISABLE;
  if (HAL_TIM_PWM_ConfigChannel(&htim12, &sConfigOC, TIM_CHANNEL_1) != HAL_OK)
  {
    Error_Handler();
  }
  if (HAL_TIM_PWM_ConfigChannel(&htim12, &sConfigOC, TIM_CHANNEL_2) != HAL_OK)
  {
    Error_Handler();
  }
  HAL_TIM_MspPostInit(&htim12);

}

static void MX_USART2_UART_Init(void)
{

  huart2.Instance = USART2;
  huart2.Init.BaudRate = 115200;
  huart2.Init.WordLength = UART_WORDLENGTH_8B;
  huart2.Init.StopBits = UART_STOPBITS_1;
  huart2.Init.Parity = UART_PARITY_NONE;
  huart2.Init.Mode = UART_MODE_TX_RX;
  huart2.Init.HwFlowCtl = UART_HWCONTROL_NONE;
  huart2.Init.OverSampling = UART_OVERSAMPLING_16;
  if (HAL_UART_Init(&huart2) != HAL_OK)
  {
    Error_Handler();
  }

}

static void MX_USART6_UART_Init(void)
{

  huart6.Instance = USART6;
  huart6.Init.BaudRate = 115200;
  huart6.Init.WordLength = UART_WORDLENGTH_8B;
  huart6.Init.StopBits = UART_STOPBITS_1;
  huart6.Init.Parity = UART_PARITY_NONE;
  huart6.Init.Mode = UART_MODE_TX_RX;
  huart6.Init.HwFlowCtl = UART_HWCONTROL_NONE;
  huart6.Init.OverSampling = UART_OVERSAMPLING_16;
  if (HAL_UART_Init(&huart6) != HAL_OK)
  {
    Error_Handler();
  }

}

static void MX_GPIO_Init(void)
{
  GPIO_InitTypeDef GPIO_InitStruct = {0};

  /* GPIO Ports Clock Enable */
  __HAL_RCC_GPIOE_CLK_ENABLE();
  __HAL_RCC_GPIOC_CLK_ENABLE();
  __HAL_RCC_GPIOH_CLK_ENABLE();
  __HAL_RCC_GPIOA_CLK_ENABLE();
  __HAL_RCC_GPIOB_CLK_ENABLE();
  __HAL_RCC_GPIOD_CLK_ENABLE();

  /*Configure GPIO pin Output Level */
  HAL_GPIO_WritePin(GPIOE, TRIG2_Pin|LMSV_Pin|LMCLK_Pin|ENPL_Pin, GPIO_PIN_RESET);

  /*Configure GPIO pin Output Level */
  HAL_GPIO_WritePin(GPIOC, TRIG1_Pin|LMDAT_Pin, GPIO_PIN_RESET);

  /*Configure GPIO pin Output Level */
  HAL_GPIO_WritePin(ENCLK_GPIO_Port, ENCLK_Pin, GPIO_PIN_SET);

  /*Configure GPIO pin Output Level */
  HAL_GPIO_WritePin(GPIOB, STRP2_Pin|STRP1_Pin, GPIO_PIN_RESET);

  /*Configure GPIO pin Output Level */
  HAL_GPIO_WritePin(GPIOD, SRDAT_Pin|SRSV_Pin|SRCLK_Pin, GPIO_PIN_RESET);

  /*Configure GPIO pin Output Level */
  HAL_GPIO_WritePin(GCS_GPIO_Port, GCS_Pin, GPIO_PIN_SET);

  /*Configure GPIO pin : TRIG2_Pin */
  GPIO_InitStruct.Pin = TRIG2_Pin;
  GPIO_InitStruct.Mode = GPIO_MODE_OUTPUT_PP;
  GPIO_InitStruct.Pull = GPIO_NOPULL;
  GPIO_InitStruct.Speed = GPIO_SPEED_FREQ_LOW;
  HAL_GPIO_Init(TRIG2_GPIO_Port, &GPIO_InitStruct);

  /*Configure GPIO pins : ECHO2_Pin ECHO1_Pin ENSO_Pin RMD11_Pin
                           RMD12_Pin */
  GPIO_InitStruct.Pin = ECHO2_Pin|ECHO1_Pin|ENSO_Pin|RMD11_Pin
                          |RMD12_Pin;
  GPIO_InitStruct.Mode = GPIO_MODE_INPUT;
  GPIO_InitStruct.Pull = GPIO_NOPULL;
  HAL_GPIO_Init(GPIOE, &GPIO_InitStruct);

  /*Configure GPIO pin : TRIG1_Pin */
  GPIO_InitStruct.Pin = TRIG1_Pin;
  GPIO_InitStruct.Mode = GPIO_MODE_OUTPUT_PP;
  GPIO_InitStruct.Pull = GPIO_NOPULL;
  GPIO_InitStruct.Speed = GPIO_SPEED_FREQ_LOW;
  HAL_GPIO_Init(TRIG1_GPIO_Port, &GPIO_InitStruct);

  /*Configure GPIO pin : LMDAT_Pin */
  GPIO_InitStruct.Pin = LMDAT_Pin;
  GPIO_InitStruct.Mode = GPIO_MODE_OUTPUT_PP;
  GPIO_InitStruct.Pull = GPIO_NOPULL;
  GPIO_InitStruct.Speed = GPIO_SPEED_FREQ_HIGH;
  HAL_GPIO_Init(LMDAT_GPIO_Port, &GPIO_InitStruct);

  /*Configure GPIO pin : BOOT1_Pin */
  GPIO_InitStruct.Pin = BOOT1_Pin;
  GPIO_InitStruct.Mode = GPIO_MODE_INPUT;
  GPIO_InitStruct.Pull = GPIO_NOPULL;
  HAL_GPIO_Init(BOOT1_GPIO_Port, &GPIO_InitStruct);

  /*Configure GPIO pins : LMSV_Pin LMCLK_Pin ENPL_Pin ENCLK_Pin */
  GPIO_InitStruct.Pin = LMSV_Pin|LMCLK_Pin|ENPL_Pin|ENCLK_Pin;
  GPIO_InitStruct.Mode = GPIO_MODE_OUTPUT_PP;
  GPIO_InitStruct.Pull = GPIO_NOPULL;
  GPIO_InitStruct.Speed = GPIO_SPEED_FREQ_HIGH;
  HAL_GPIO_Init(GPIOE, &GPIO_InitStruct);

  /*Configure GPIO pins : STRP2_Pin STRP1_Pin */
  GPIO_InitStruct.Pin = STRP2_Pin|STRP1_Pin;
  GPIO_InitStruct.Mode = GPIO_MODE_OUTPUT_PP;
  GPIO_InitStruct.Pull = GPIO_NOPULL;
  GPIO_InitStruct.Speed = GPIO_SPEED_FREQ_LOW;
  HAL_GPIO_Init(GPIOB, &GPIO_InitStruct);

  /*Configure GPIO pins : SRDAT_Pin SRSV_Pin SRCLK_Pin */
  GPIO_InitStruct.Pin = SRDAT_Pin|SRSV_Pin|SRCLK_Pin;
  GPIO_InitStruct.Mode = GPIO_MODE_OUTPUT_PP;
  GPIO_InitStruct.Pull = GPIO_NOPULL;
  GPIO_InitStruct.Speed = GPIO_SPEED_FREQ_HIGH;
  HAL_GPIO_Init(GPIOD, &GPIO_InitStruct);

  /*Configure GPIO pins : DRE1_Pin RMD7_Pin RMD8_Pin RMD9_Pin
                           RMD10_Pin */
  GPIO_InitStruct.Pin = DRE1_Pin|RMD7_Pin|RMD8_Pin|RMD9_Pin
                          |RMD10_Pin;
  GPIO_InitStruct.Mode = GPIO_MODE_INPUT;
  GPIO_InitStruct.Pull = GPIO_NOPULL;
  HAL_GPIO_Init(GPIOD, &GPIO_InitStruct);

  /*Configure GPIO pin : DRE2_Pin */
  GPIO_InitStruct.Pin = DRE2_Pin;
  GPIO_InitStruct.Mode = GPIO_MODE_INPUT;
  GPIO_InitStruct.Pull = GPIO_NOPULL;
  HAL_GPIO_Init(DRE2_GPIO_Port, &GPIO_InitStruct);

  /*Configure GPIO pin : DRESW_Pin */
  GPIO_InitStruct.Pin = DRESW_Pin;
  GPIO_InitStruct.Mode = GPIO_MODE_INPUT;
  GPIO_InitStruct.Pull = GPIO_NOPULL;
  HAL_GPIO_Init(DRESW_GPIO_Port, &GPIO_InitStruct);

  /*Configure GPIO pin : GCS_Pin */
  GPIO_InitStruct.Pin = GCS_Pin;
  GPIO_InitStruct.Mode = GPIO_MODE_OUTPUT_PP;
  GPIO_InitStruct.Pull = GPIO_NOPULL;
  GPIO_InitStruct.Speed = GPIO_SPEED_FREQ_HIGH;
  HAL_GPIO_Init(GCS_GPIO_Port, &GPIO_InitStruct);

  /*Configure GPIO pins : GINT2_Pin GINT1_Pin */
  GPIO_InitStruct.Pin = GINT2_Pin|GINT1_Pin;
  GPIO_InitStruct.Mode = GPIO_MODE_IT_RISING;
  GPIO_InitStruct.Pull = GPIO_NOPULL;
  HAL_GPIO_Init(GPIOD, &GPIO_InitStruct);

  /* EXTI interrupt init*/
  HAL_NVIC_SetPriority(EXTI0_IRQn, 0, 0);
  HAL_NVIC_EnableIRQ(EXTI0_IRQn);

  HAL_NVIC_SetPriority(EXTI1_IRQn, 0, 0);
  HAL_NVIC_EnableIRQ(EXTI1_IRQn);

}

/* USER CODE BEGIN 4 */
void HAL_TIM_PeriodElapsedCallback(TIM_HandleTypeDef *htim) {
	if (htim == &htim5) {
		registerHandler();
	} else { //Timer 7 for digital read of UI

	}
}
/* USER CODE END 4 */

void Error_Handler(void)
{
	__disable_irq();
	while (1) {
	}
}
